AUTOSAR XML (schema 00047)
package /Svc_StbM/ClientServerInterfaces
  12 x client server interface:
    GlobalTime_Master_CertTime: is-service=true
      6 x operation, all with possible-error=[GlobalTime_Master_CertTime/E_NOT_OK, GlobalTime_Master_CertTime/E_OK]:
        GetMasterConfig
          arg masterConfig: type=StbM_MasterConfigType, direction=OUT
        SetGlobalTime
          arg timeStamp: type=StbM_TimeStampType, direction=IN
          arg userData: type=StbM_UserDataType, direction=IN
        SetRateCorrection
          arg rateDeviation: type=StbM_RateDeviationType, direction=IN
        SetUserData
          arg userData: type=StbM_UserDataType, direction=IN
        TriggerTimeTransmission
        UpdateGlobalTime
          arg timeStamp: type=StbM_TimeStampType, direction=IN
          arg userData: type=StbM_UserDataType, direction=IN
      error E_NOT_OK: error-code=1
      error E_OK: error-code=0
    GlobalTime_Master_Offset0: is-service=true
      7 x operation, all with possible-error=[GlobalTime_Master_Offset0/E_NOT_OK, GlobalTime_Master_Offset0/E_OK]:
        GetMasterConfig
          arg masterConfig: type=StbM_MasterConfigType, direction=OUT
        SetGlobalTime
          arg timeStamp: type=StbM_TimeStampType, direction=IN
          arg userData: type=StbM_UserDataType, direction=IN
        SetOffset
          arg timeStamp: type=StbM_TimeStampType, direction=IN
          arg userData: type=StbM_UserDataType, direction=IN
        SetRateCorrection
          arg rateDeviation: type=StbM_RateDeviationType, direction=IN
        SetUserData
          arg userData: type=StbM_UserDataType, direction=IN
        TriggerTimeTransmission
        UpdateGlobalTime
          arg timeStamp: type=StbM_TimeStampType, direction=IN
          arg userData: type=StbM_UserDataType, direction=IN
      error E_NOT_OK: error-code=1
      error E_OK: error-code=0
    GlobalTime_Master_Provider0: is-service=true
      6 x operation, all with possible-error=[GlobalTime_Master_Provider0/E_NOT_OK, GlobalTime_Master_Provider0/E_OK]:
        GetMasterConfig
          arg masterConfig: type=StbM_MasterConfigType, direction=OUT
        SetGlobalTime
          arg timeStamp: type=StbM_TimeStampType, direction=IN
          arg userData: type=StbM_UserDataType, direction=IN
        SetRateCorrection
          arg rateDeviation: type=StbM_RateDeviationType, direction=IN
        SetUserData
          arg userData: type=StbM_UserDataType, direction=IN
        TriggerTimeTransmission
        UpdateGlobalTime
          arg timeStamp: type=StbM_TimeStampType, direction=IN
          arg userData: type=StbM_UserDataType, direction=IN
      error E_NOT_OK: error-code=1
      error E_OK: error-code=0
    GlobalTime_Master_Provider1: is-service=true
      6 x operation, all with possible-error=[GlobalTime_Master_Provider1/E_NOT_OK, GlobalTime_Master_Provider1/E_OK]:
        GetMasterConfig
          arg masterConfig: type=StbM_MasterConfigType, direction=OUT
        SetGlobalTime
          arg timeStamp: type=StbM_TimeStampType, direction=IN
          arg userData: type=StbM_UserDataType, direction=IN
        SetRateCorrection
          arg rateDeviation: type=StbM_RateDeviationType, direction=IN
        SetUserData
          arg userData: type=StbM_UserDataType, direction=IN
        TriggerTimeTransmission
        UpdateGlobalTime
          arg timeStamp: type=StbM_TimeStampType, direction=IN
          arg userData: type=StbM_UserDataType, direction=IN
      error E_NOT_OK: error-code=1
      error E_OK: error-code=0
    GlobalTime_Slave_CertTime: is-service=true
      5 x operation, all with possible-error=[GlobalTime_Slave_CertTime/E_NOT_OK, GlobalTime_Slave_CertTime/E_OK]:
        GetCurrentTime
          arg timeStamp: type=StbM_TimeStampType, direction=OUT
          arg userData: type=StbM_UserDataType, direction=OUT
        GetCurrentTimeExtended
          arg timeStamp: type=StbM_TimeStampExtendedType, direction=OUT
          arg userData: type=StbM_UserDataType, direction=OUT
        GetRateDeviation
          arg rateDeviation: type=StbM_RateDeviationType, direction=OUT
        GetTimeBaseStatus
          arg syncTimeBaseStatus: type=StbM_TimeBaseStatusType, direction=OUT
          arg offsetTimeBaseStatus: type=StbM_TimeBaseStatusType, direction=OUT
        GetTimeLeap
          arg timeJump: type=StbM_TimeDiffType, direction=OUT
      error E_NOT_OK: error-code=1
      error E_OK: error-code=0
    GlobalTime_Slave_Client0: is-service=true
      6 x operation, all with possible-error=[GlobalTime_Slave_Client0/E_NOT_OK, GlobalTime_Slave_Client0/E_OK]:
        GetCurrentTime
          arg timeStamp: type=StbM_TimeStampType, direction=OUT
          arg userData: type=StbM_UserDataType, direction=OUT
        GetCurrentTimeExtended
          arg timeStamp: type=StbM_TimeStampExtendedType, direction=OUT
          arg userData: type=StbM_UserDataType, direction=OUT
        GetRateDeviation
          arg rateDeviation: type=StbM_RateDeviationType, direction=OUT
        GetSyncTimeRecordHead
          arg syncRecordTableHead: type=StbM_SyncRecordTableHeadType, direction=OUT
        GetTimeBaseStatus
          arg syncTimeBaseStatus: type=StbM_TimeBaseStatusType, direction=OUT
          arg offsetTimeBaseStatus: type=StbM_TimeBaseStatusType, direction=OUT
        GetTimeLeap
          arg timeJump: type=StbM_TimeDiffType, direction=OUT
      error E_NOT_OK: error-code=1
      error E_OK: error-code=0
    GlobalTime_Slave_Offset0: is-service=true
      5 x operation, all with possible-error=[GlobalTime_Slave_Offset0/E_NOT_OK, GlobalTime_Slave_Offset0/E_OK]:
        GetCurrentTime
          arg timeStamp: type=StbM_TimeStampType, direction=OUT
          arg userData: type=StbM_UserDataType, direction=OUT
        GetCurrentTimeExtended
          arg timeStamp: type=StbM_TimeStampExtendedType, direction=OUT
          arg userData: type=StbM_UserDataType, direction=OUT
        GetRateDeviation
          arg rateDeviation: type=StbM_RateDeviationType, direction=OUT
        GetTimeBaseStatus
          arg syncTimeBaseStatus: type=StbM_TimeBaseStatusType, direction=OUT
          arg offsetTimeBaseStatus: type=StbM_TimeBaseStatusType, direction=OUT
        GetTimeLeap
          arg timeJump: type=StbM_TimeDiffType, direction=OUT
      error E_NOT_OK: error-code=1
      error E_OK: error-code=0
    GlobalTime_Slave_Provider0: is-service=true
      5 x operation, all with possible-error=[GlobalTime_Slave_Provider0/E_NOT_OK, GlobalTime_Slave_Provider0/E_OK]:
        GetCurrentTime
          arg timeStamp: type=StbM_TimeStampType, direction=OUT
          arg userData: type=StbM_UserDataType, direction=OUT
        GetCurrentTimeExtended
          arg timeStamp: type=StbM_TimeStampExtendedType, direction=OUT
          arg userData: type=StbM_UserDataType, direction=OUT
        GetRateDeviation
          arg rateDeviation: type=StbM_RateDeviationType, direction=OUT
        GetTimeBaseStatus
          arg syncTimeBaseStatus: type=StbM_TimeBaseStatusType, direction=OUT
          arg offsetTimeBaseStatus: type=StbM_TimeBaseStatusType, direction=OUT
        GetTimeLeap
          arg timeJump: type=StbM_TimeDiffType, direction=OUT
      error E_NOT_OK: error-code=1
      error E_OK: error-code=0
    GlobalTime_Slave_Provider1: is-service=true
      5 x operation, all with possible-error=[GlobalTime_Slave_Provider1/E_NOT_OK, GlobalTime_Slave_Provider1/E_OK]:
        GetCurrentTime
          arg timeStamp: type=StbM_TimeStampType, direction=OUT
          arg userData: type=StbM_UserDataType, direction=OUT
        GetCurrentTimeExtended
          arg timeStamp: type=StbM_TimeStampExtendedType, direction=OUT
          arg userData: type=StbM_UserDataType, direction=OUT
        GetRateDeviation
          arg rateDeviation: type=StbM_RateDeviationType, direction=OUT
        GetTimeBaseStatus
          arg syncTimeBaseStatus: type=StbM_TimeBaseStatusType, direction=OUT
          arg offsetTimeBaseStatus: type=StbM_TimeBaseStatusType, direction=OUT
        GetTimeLeap
          arg timeJump: type=StbM_TimeDiffType, direction=OUT
      error E_NOT_OK: error-code=1
      error E_OK: error-code=0
    MeasurementNotification_Client0
      operation SetSyncTimeRecordTable: possible-error=[MeasurementNotification_Client0/E_NOT_OK, MeasurementNotification_Client0/E_OK]
        arg syncRecordTableBlock: type=StbM_SyncRecordTableBlockType, direction=IN
      error E_NOT_OK: error-code=1
      error E_OK: error-code=0
    StartTimer: is-service=true
      operation StartTimer: possible-error=[StartTimer/E_NOT_OK, StartTimer/E_OK]
        arg expireTime: type=StbM_TimeStampType, direction=IN
      error E_NOT_OK: error-code=1
      error E_OK: error-code=0
    TimeNotification: is-service=true
      operation NotifyTime: possible-error=[TimeNotification/E_NOT_OK, TimeNotification/E_OK]
        arg deviationTime: type=StbM_TimeDiffType, direction=IN
      error E_NOT_OK: error-code=1
      error E_OK: error-code=0
package /Svc_StbM/ImplementationDataTypes
  14 x impl type:
    StbM_CustomerIdType: category=VALUE, base-type=uint16, is-struct-with-optional-element=false
    StbM_MasterConfigType: category=VALUE, base-type=uint8, is-struct-with-optional-element=false
    StbM_OffsetRecordTableBlockType: category=STRUCTURE, is-struct-with-optional-element=true
      element GlbSeconds: category=VALUE, base-type=uint32
      element GlbNanoSeconds: category=VALUE, base-type=uint32
      element TimeBaseStatus: category=VALUE, base-type=uint8
    StbM_OffsetRecordTableHeadType: category=STRUCTURE, is-struct-with-optional-element=true
      element OffsetTimeDomain: category=VALUE, base-type=uint8
    StbM_RateDeviationType: category=VALUE, base-type=sint16, is-struct-with-optional-element=false
    StbM_SyncRecordTableBlockType: category=STRUCTURE, is-struct-with-optional-element=true
      8 x element, all with category=VALUE:
        GlbSeconds: base-type=uint32
        GlbNanoSeconds: base-type=uint32
        TimeBaseStatus: base-type=uint8
        VirtualLocalTimeLow: base-type=uint32
        RateDeviation: base-type=sint16
        LocSeconds: base-type=uint32
        LocNanoSeconds: base-type=uint32
        PathDelay: base-type=uint32
    StbM_SyncRecordTableHeadType: category=STRUCTURE, is-struct-with-optional-element=true
      element SynchronizedTimeDomain: category=VALUE, base-type=uint8
      element HWfrequency: category=VALUE, base-type=uint32
      element HWprescaler: category=VALUE, base-type=uint32
    StbM_SynchronizedTimeBaseType: category=VALUE, base-type=uint16, is-struct-with-optional-element=false
    StbM_TimeBaseNotificationType: category=VALUE, base-type=uint32, is-struct-with-optional-element=false
    StbM_TimeBaseStatusType: category=VALUE, base-type=uint8, is-struct-with-optional-element=false
    StbM_TimeDiffType: category=VALUE, base-type=sint32, is-struct-with-optional-element=false
    StbM_TimeStampExtendedType: category=STRUCTURE, is-struct-with-optional-element=true
      element timeBaseStatus: category=VALUE, base-type=uint8
      element nanoseconds: category=VALUE, base-type=uint32
      element seconds: category=VALUE, base-type=uint64
    StbM_TimeStampType: category=STRUCTURE, is-struct-with-optional-element=true
      4 x element, all with category=VALUE:
        timeBaseStatus: base-type=uint8
        nanoseconds: base-type=uint32
        seconds: base-type=uint32
        secondsHi: base-type=uint16
    StbM_UserDataType: category=STRUCTURE, is-struct-with-optional-element=true
      4 x element, all with category=VALUE:
        userDataLength: base-type=uint16
        userByte{0..2}: base-type=uint8
package /Svc_StbM/SenderReceiverInterfaces
  sender receiver interface StatusNotification
    data eventNotification: type=StbM_TimeBaseNotificationType, init-value=0
package /Svc_StbM/SwComponentTypes
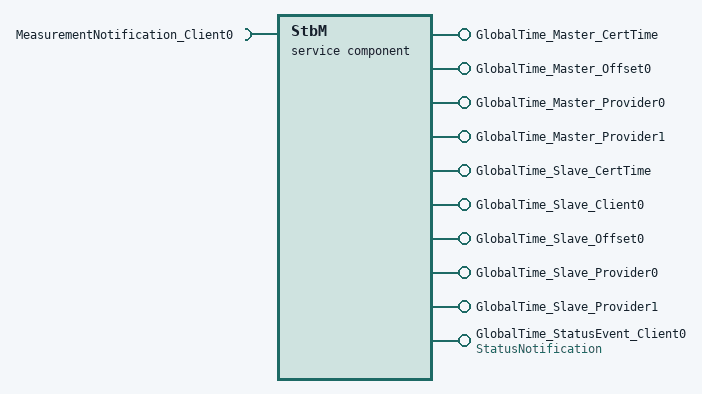
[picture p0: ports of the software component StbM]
  service sw component type StbM
    10 x provide port:
      GlobalTime_Master_CertTime: provided-interface=GlobalTime_Master_CertTime
        provided-com-specs:
          operation=GlobalTime_Master_CertTime/GetMasterConfig, queue-length=1
          operation=GlobalTime_Master_CertTime/SetGlobalTime, queue-length=1
          operation=GlobalTime_Master_CertTime/SetRateCorrection, queue-length=1
          operation=GlobalTime_Master_CertTime/SetUserData, queue-length=1
          operation=GlobalTime_Master_CertTime/TriggerTimeTransmission, queue-length=1
          operation=GlobalTime_Master_CertTime/UpdateGlobalTime, queue-length=1
      GlobalTime_Master_Offset0: provided-interface=GlobalTime_Master_Offset0
        provided-com-specs:
          operation=GlobalTime_Master_Offset0/GetMasterConfig, queue-length=1
          operation=GlobalTime_Master_Offset0/SetGlobalTime, queue-length=1
          operation=SetOffset, queue-length=1
          operation=GlobalTime_Master_Offset0/SetRateCorrection, queue-length=1
          operation=GlobalTime_Master_Offset0/SetUserData, queue-length=1
          operation=GlobalTime_Master_Offset0/TriggerTimeTransmission, queue-length=1
          operation=GlobalTime_Master_Offset0/UpdateGlobalTime, queue-length=1
      GlobalTime_Master_Provider0: provided-interface=GlobalTime_Master_Provider0
        provided-com-specs:
          operation=GlobalTime_Master_Provider0/GetMasterConfig, queue-length=1
          operation=GlobalTime_Master_Provider0/SetGlobalTime, queue-length=1
          operation=GlobalTime_Master_Provider0/SetRateCorrection, queue-length=1
          operation=GlobalTime_Master_Provider0/SetUserData, queue-length=1
          operation=GlobalTime_Master_Provider0/TriggerTimeTransmission, queue-length=1
          operation=GlobalTime_Master_Provider0/UpdateGlobalTime, queue-length=1
      GlobalTime_Master_Provider1: provided-interface=GlobalTime_Master_Provider1
        provided-com-specs:
          operation=GlobalTime_Master_Provider1/GetMasterConfig, queue-length=1
          operation=GlobalTime_Master_Provider1/SetGlobalTime, queue-length=1
          operation=GlobalTime_Master_Provider1/SetRateCorrection, queue-length=1
          operation=GlobalTime_Master_Provider1/SetUserData, queue-length=1
          operation=GlobalTime_Master_Provider1/TriggerTimeTransmission, queue-length=1
          operation=GlobalTime_Master_Provider1/UpdateGlobalTime, queue-length=1
      GlobalTime_Slave_CertTime: provided-interface=GlobalTime_Slave_CertTime
        provided-com-specs:
          operation=GlobalTime_Slave_CertTime/GetCurrentTime, queue-length=1
          operation=GlobalTime_Slave_CertTime/GetCurrentTimeExtended, queue-length=1
          operation=GlobalTime_Slave_CertTime/GetRateDeviation, queue-length=1
          operation=GlobalTime_Slave_CertTime/GetTimeBaseStatus, queue-length=1
          operation=GlobalTime_Slave_CertTime/GetTimeLeap, queue-length=1
      GlobalTime_Slave_Client0: provided-interface=GlobalTime_Slave_Client0
        provided-com-specs:
          operation=GlobalTime_Slave_Client0/GetCurrentTime, queue-length=1
          operation=GlobalTime_Slave_Client0/GetCurrentTimeExtended, queue-length=1
          operation=GetSyncTimeRecordHead, queue-length=1
          operation=GlobalTime_Slave_Client0/GetRateDeviation, queue-length=1
          operation=GlobalTime_Slave_Client0/GetTimeBaseStatus, queue-length=1
          operation=GlobalTime_Slave_Client0/GetTimeLeap, queue-length=1
      GlobalTime_Slave_Offset0: provided-interface=GlobalTime_Slave_Offset0
        provided-com-specs:
          operation=GlobalTime_Slave_Offset0/GetCurrentTime, queue-length=1
          operation=GlobalTime_Slave_Offset0/GetCurrentTimeExtended, queue-length=1
          operation=GlobalTime_Slave_Offset0/GetRateDeviation, queue-length=1
          operation=GlobalTime_Slave_Offset0/GetTimeBaseStatus, queue-length=1
          operation=GlobalTime_Slave_Offset0/GetTimeLeap, queue-length=1
      GlobalTime_Slave_Provider0: provided-interface=GlobalTime_Slave_Provider0
        provided-com-specs:
          operation=GlobalTime_Slave_Provider0/GetCurrentTime, queue-length=1
          operation=GlobalTime_Slave_Provider0/GetCurrentTimeExtended, queue-length=1
          operation=GlobalTime_Slave_Provider0/GetRateDeviation, queue-length=1
          operation=GlobalTime_Slave_Provider0/GetTimeBaseStatus, queue-length=1
          operation=GlobalTime_Slave_Provider0/GetTimeLeap, queue-length=1
      GlobalTime_Slave_Provider1: provided-interface=GlobalTime_Slave_Provider1
        provided-com-specs:
          operation=GlobalTime_Slave_Provider1/GetCurrentTime, queue-length=1
          operation=GlobalTime_Slave_Provider1/GetCurrentTimeExtended, queue-length=1
          operation=GlobalTime_Slave_Provider1/GetRateDeviation, queue-length=1
          operation=GlobalTime_Slave_Provider1/GetTimeBaseStatus, queue-length=1
          operation=GlobalTime_Slave_Provider1/GetTimeLeap, queue-length=1
      GlobalTime_StatusEvent_Client0: nonqueued-sender-com-spec=data-element=eventNotification, provided-interface=StatusNotification
    require port MeasurementNotification_Client0: client-com-spec=SetSyncTimeRecordTable, required-interface=MeasurementNotification_Client0
    behavior StbMInternalBehavior: handle-termination-and-restart=NO-SUPPORT, included-data-type-set
      51 x operation invoked event:
        OIE_GlobalTime_Master_CertTime_GetMasterConfig: start-on-event=GetMasterConfig, operation=GlobalTime_Master_CertTime.GetMasterConfig
        OIE_GlobalTime_Master_CertTime_SetGlobalTime: start-on-event=SetGlobalTime, operation=GlobalTime_Master_CertTime.SetGlobalTime
        OIE_GlobalTime_Master_CertTime_SetRateCorrection: start-on-event=SetRateCorrection, operation=GlobalTime_Master_CertTime.SetRateCorrection
        OIE_GlobalTime_Master_CertTime_SetUserData: start-on-event=SetUserData, operation=GlobalTime_Master_CertTime.SetUserData
        OIE_GlobalTime_Master_CertTime_TriggerTimeTransmission: start-on-event=TriggerTimeTransmission, operation=GlobalTime_Master_CertTime.TriggerTimeTransmission
        OIE_GlobalTime_Master_CertTime_UpdateGlobalTime: start-on-event=UpdateGlobalTime, operation=GlobalTime_Master_CertTime.UpdateGlobalTime
        OIE_GlobalTime_Master_Offset0_GetMasterConfig: start-on-event=GetMasterConfig, operation=GlobalTime_Master_Offset0.GetMasterConfig
        OIE_GlobalTime_Master_Offset0_SetGlobalTime: start-on-event=SetGlobalTime, operation=GlobalTime_Master_Offset0.SetGlobalTime
        OIE_GlobalTime_Master_Offset0_SetOffset: start-on-event=SetOffset, operation=GlobalTime_Master_Offset0.SetOffset
        OIE_GlobalTime_Master_Offset0_SetRateCorrection: start-on-event=SetRateCorrection, operation=GlobalTime_Master_Offset0.SetRateCorrection
        OIE_GlobalTime_Master_Offset0_SetUserData: start-on-event=SetUserData, operation=GlobalTime_Master_Offset0.SetUserData
        OIE_GlobalTime_Master_Offset0_TriggerTimeTransmission: start-on-event=TriggerTimeTransmission, operation=GlobalTime_Master_Offset0.TriggerTimeTransmission
        OIE_GlobalTime_Master_Offset0_UpdateGlobalTime: start-on-event=UpdateGlobalTime, operation=GlobalTime_Master_Offset0.UpdateGlobalTime
        OIE_GlobalTime_Master_Provider0_GetMasterConfig: start-on-event=GetMasterConfig, operation=GlobalTime_Master_Provider0.GetMasterConfig
        OIE_GlobalTime_Master_Provider0_SetGlobalTime: start-on-event=SetGlobalTime, operation=GlobalTime_Master_Provider0.SetGlobalTime
        OIE_GlobalTime_Master_Provider0_SetRateCorrection: start-on-event=SetRateCorrection, operation=GlobalTime_Master_Provider0.SetRateCorrection
        OIE_GlobalTime_Master_Provider0_SetUserData: start-on-event=SetUserData, operation=GlobalTime_Master_Provider0.SetUserData
        OIE_GlobalTime_Master_Provider0_TriggerTimeTransmission: start-on-event=TriggerTimeTransmission, operation=GlobalTime_Master_Provider0.TriggerTimeTransmission
        OIE_GlobalTime_Master_Provider0_UpdateGlobalTime: start-on-event=UpdateGlobalTime, operation=GlobalTime_Master_Provider0.UpdateGlobalTime
        OIE_GlobalTime_Master_Provider1_GetMasterConfig: start-on-event=GetMasterConfig, operation=GlobalTime_Master_Provider1.GetMasterConfig
        OIE_GlobalTime_Master_Provider1_SetGlobalTime: start-on-event=SetGlobalTime, operation=GlobalTime_Master_Provider1.SetGlobalTime
        OIE_GlobalTime_Master_Provider1_SetRateCorrection: start-on-event=SetRateCorrection, operation=GlobalTime_Master_Provider1.SetRateCorrection
        OIE_GlobalTime_Master_Provider1_SetUserData: start-on-event=SetUserData, operation=GlobalTime_Master_Provider1.SetUserData
        OIE_GlobalTime_Master_Provider1_TriggerTimeTransmission: start-on-event=TriggerTimeTransmission, operation=GlobalTime_Master_Provider1.TriggerTimeTransmission
        OIE_GlobalTime_Master_Provider1_UpdateGlobalTime: start-on-event=UpdateGlobalTime, operation=GlobalTime_Master_Provider1.UpdateGlobalTime
        OIE_GlobalTime_Slave_CertTime_GetCurrentTime: start-on-event=GetCurrentTime, operation=GlobalTime_Slave_CertTime.GetCurrentTime
        OIE_GlobalTime_Slave_CertTime_GetCurrentTimeExtended: start-on-event=GetCurrentTimeExtended, operation=GlobalTime_Slave_CertTime.GetCurrentTimeExtended
        OIE_GlobalTime_Slave_CertTime_GetRateDeviation: start-on-event=GetRateDeviation, operation=GlobalTime_Slave_CertTime.GetRateDeviation
        OIE_GlobalTime_Slave_CertTime_GetTimeBaseStatus: start-on-event=GetTimeBaseStatus, operation=GlobalTime_Slave_CertTime.GetTimeBaseStatus
        OIE_GlobalTime_Slave_CertTime_GetTimeLeap: start-on-event=GetTimeLeap, operation=GlobalTime_Slave_CertTime.GetTimeLeap
        OIE_GlobalTime_Slave_Client0_GetCurrentTime: start-on-event=GetCurrentTime, operation=GlobalTime_Slave_Client0.GetCurrentTime
        OIE_GlobalTime_Slave_Client0_GetCurrentTimeExtended: start-on-event=GetCurrentTimeExtended, operation=GlobalTime_Slave_Client0.GetCurrentTimeExtended
        OIE_GlobalTime_Slave_Client0_GetRateDeviation: start-on-event=GetRateDeviation, operation=GlobalTime_Slave_Client0.GetRateDeviation
        OIE_GlobalTime_Slave_Client0_GetSyncTimeRecordHead: start-on-event=GetSyncTimeRecordHead, operation=GlobalTime_Slave_Client0.GetSyncTimeRecordHead
        OIE_GlobalTime_Slave_Client0_GetTimeBaseStatus: start-on-event=GetTimeBaseStatus, operation=GlobalTime_Slave_Client0.GetTimeBaseStatus
        OIE_GlobalTime_Slave_Client0_GetTimeLeap: start-on-event=GetTimeLeap, operation=GlobalTime_Slave_Client0.GetTimeLeap
        OIE_GlobalTime_Slave_Offset0_GetCurrentTime: start-on-event=GetCurrentTime, operation=GlobalTime_Slave_Offset0.GetCurrentTime
        OIE_GlobalTime_Slave_Offset0_GetCurrentTimeExtended: start-on-event=GetCurrentTimeExtended, operation=GlobalTime_Slave_Offset0.GetCurrentTimeExtended
        OIE_GlobalTime_Slave_Offset0_GetRateDeviation: start-on-event=GetRateDeviation, operation=GlobalTime_Slave_Offset0.GetRateDeviation
        OIE_GlobalTime_Slave_Offset0_GetTimeBaseStatus: start-on-event=GetTimeBaseStatus, operation=GlobalTime_Slave_Offset0.GetTimeBaseStatus
        OIE_GlobalTime_Slave_Offset0_GetTimeLeap: start-on-event=GetTimeLeap, operation=GlobalTime_Slave_Offset0.GetTimeLeap
        OIE_GlobalTime_Slave_Provider0_GetCurrentTime: start-on-event=GetCurrentTime, operation=GlobalTime_Slave_Provider0.GetCurrentTime
        OIE_GlobalTime_Slave_Provider0_GetCurrentTimeExtended: start-on-event=GetCurrentTimeExtended, operation=GlobalTime_Slave_Provider0.GetCurrentTimeExtended
        OIE_GlobalTime_Slave_Provider0_GetRateDeviation: start-on-event=GetRateDeviation, operation=GlobalTime_Slave_Provider0.GetRateDeviation
        OIE_GlobalTime_Slave_Provider0_GetTimeBaseStatus: start-on-event=GetTimeBaseStatus, operation=GlobalTime_Slave_Provider0.GetTimeBaseStatus
        OIE_GlobalTime_Slave_Provider0_GetTimeLeap: start-on-event=GetTimeLeap, operation=GlobalTime_Slave_Provider0.GetTimeLeap
        OIE_GlobalTime_Slave_Provider1_GetCurrentTime: start-on-event=GetCurrentTime, operation=GlobalTime_Slave_Provider1.GetCurrentTime
        OIE_GlobalTime_Slave_Provider1_GetCurrentTimeExtended: start-on-event=GetCurrentTimeExtended, operation=GlobalTime_Slave_Provider1.GetCurrentTimeExtended
        OIE_GlobalTime_Slave_Provider1_GetRateDeviation: start-on-event=GetRateDeviation, operation=GlobalTime_Slave_Provider1.GetRateDeviation
        OIE_GlobalTime_Slave_Provider1_GetTimeBaseStatus: start-on-event=GetTimeBaseStatus, operation=GlobalTime_Slave_Provider1.GetTimeBaseStatus
        OIE_GlobalTime_Slave_Provider1_GetTimeLeap: start-on-event=GetTimeLeap, operation=GlobalTime_Slave_Provider1.GetTimeLeap
      port-api-options:
        {indirect-api=false, port-defined-argument-value{value=1, value-type=StbM_SynchronizedTimeBaseType}, port=GlobalTime_Master_Provider0}
        {indirect-api=false, port-defined-argument-value{value=16, value-type=StbM_SynchronizedTimeBaseType}, port=GlobalTime_Master_Offset0}
        {indirect-api=false, port-defined-argument-value{value=2, value-type=StbM_SynchronizedTimeBaseType}, port=GlobalTime_Master_Provider1}
        {indirect-api=false, port-defined-argument-value{value=3, value-type=StbM_SynchronizedTimeBaseType}, port=GlobalTime_Master_CertTime}
        {indirect-api=false, port-defined-argument-value{value=0, value-type=StbM_SynchronizedTimeBaseType}, port=GlobalTime_Slave_Client0}
        {indirect-api=false, port-defined-argument-value{value=1, value-type=StbM_SynchronizedTimeBaseType}, port=GlobalTime_Slave_Provider0}
        {indirect-api=false, port-defined-argument-value{value=16, value-type=StbM_SynchronizedTimeBaseType}, port=GlobalTime_Slave_Offset0}
        {indirect-api=false, port-defined-argument-value{value=2, value-type=StbM_SynchronizedTimeBaseType}, port=GlobalTime_Slave_Provider1}
        {indirect-api=false, port-defined-argument-value{value=3, value-type=StbM_SynchronizedTimeBaseType}, port=GlobalTime_Slave_CertTime}
      22 x runnable:
        BusGetCurrentTime: can-be-invoked-concurrently=true, symbol=StbM_BusGetCurrentTime
        BusSetGlobalTime: can-be-invoked-concurrently=true, symbol=StbM_BusSetGlobalTime
        GetCurrentTime: can-be-invoked-concurrently=true, symbol=StbM_GetCurrentTime
        GetCurrentTimeExtended: can-be-invoked-concurrently=true, symbol=StbM_GetCurrentTimeExtended
        GetCurrentVirtualLocalTime: can-be-invoked-concurrently=true, symbol=StbM_GetCurrentVirtualLocalTime
        GetMasterConfig: can-be-invoked-concurrently=true, symbol=StbM_GetMasterConfig
        GetOffset: can-be-invoked-concurrently=true, symbol=StbM_GetOffset
        GetOffsetTimeRecordHead: can-be-invoked-concurrently=true, symbol=StbM_GetOffsetTimeRecordHead
        GetRateDeviation: can-be-invoked-concurrently=true, symbol=StbM_GetRateDeviation
        GetSyncTimeRecordHead: can-be-invoked-concurrently=true, symbol=StbM_GetSyncTimeRecordHead
        GetTimeBaseStatus: can-be-invoked-concurrently=true, symbol=StbM_GetTimeBaseStatus
        GetTimeBaseUpdateCounter: can-be-invoked-concurrently=true, symbol=StbM_GetTimeBaseUpdateCounter
        GetTimeLeap: can-be-invoked-concurrently=true, symbol=StbM_GetTimeLeap
        MainFunction: minimum-start-interval=0.005, symbol=StbM_MainFunction
        SetGlobalTime: can-be-invoked-concurrently=true, symbol=StbM_SetGlobalTime
        SetOffset: can-be-invoked-concurrently=true, symbol=StbM_SetOffset
        SetRateCorrection: can-be-invoked-concurrently=true, symbol=StbM_SetRateCorrection
        SetUserData: can-be-invoked-concurrently=true, symbol=StbM_SetUserData
        StartTimer: can-be-invoked-concurrently=true, symbol=StbM_StartTimer
        StbM_Required_Port: can-be-invoked-concurrently=true, symbol=StbM_Required_Ports_Call
          data-send-points:
            access GlobalTime_StatusEvent_Client0: accessed-variable=GlobalTime_StatusEvent_Client0.eventNotification
          sync call MeasurementNotification_Client0: operation=MeasurementNotification_Client0.SetSyncTimeRecordTable
        TriggerTimeTransmission: can-be-invoked-concurrently=true, symbol=StbM_TriggerTimeTransmission
        UpdateGlobalTime: can-be-invoked-concurrently=true, symbol=StbM_UpdateGlobalTime
  swc implementation StbM_SwcImplementation: programming-language=C, sw-version=1.0.0, swc-bsw-mapping=SwcBswMapping_StbM, vendor-id=76, behavior=StbMInternalBehavior
    code-descriptors:
      code CodeDescriptor: artifact-descriptors=autosar-engineering-object={short-label=StbM_LibObjects, category=SWLIB, domain=AUTOSAR_STBM}
    resource consumption ResourceConsumption
  swc bsw mapping SwcBswMapping_StbM: bsw-behavior=BswInternalBehavior_StbM, swc-behavior=StbMInternalBehavior
    runnable-mappings:
      bsw-entity=BswCE_StbM_BusGetCurrentTime, swc-runnable=BusGetCurrentTime
      bsw-entity=BswCE_StbM_BusSetGlobalTime, swc-runnable=BusSetGlobalTime
      bsw-entity=BswCE_StbM_GetCurrentTime, swc-runnable=GetCurrentTime
      bsw-entity=BswCE_StbM_GetCurrentTimeExtended, swc-runnable=GetCurrentTimeExtended
      bsw-entity=BswCE_StbM_GetCurrentVirtualLocalTime, swc-runnable=GetCurrentVirtualLocalTime
      bsw-entity=BswCE_StbM_GetMasterConfig, swc-runnable=GetMasterConfig
      bsw-entity=BswCE_StbM_GetOffset, swc-runnable=GetOffset
      bsw-entity=BswCE_StbM_GetOffsetTimeRecordHead, swc-runnable=GetOffsetTimeRecordHead
      bsw-entity=BswCE_StbM_GetRateDeviation, swc-runnable=GetRateDeviation
      bsw-entity=BswCE_StbM_GetSyncTimeRecordHead, swc-runnable=GetSyncTimeRecordHead
      bsw-entity=BswCE_StbM_GetTimeBaseStatus, swc-runnable=GetTimeBaseStatus
      bsw-entity=BswCE_StbM_GetTimeBaseUpdateCounter, swc-runnable=GetTimeBaseUpdateCounter
      bsw-entity=BswCE_StbM_GetTimeLeap, swc-runnable=GetTimeLeap
      bsw-entity=BswSE_StbM_MainFunction, swc-runnable=MainFunction
      bsw-entity=BswCE_StbM_SetGlobalTime, swc-runnable=SetGlobalTime
      bsw-entity=BswCE_StbM_SetOffset, swc-runnable=SetOffset
      bsw-entity=BswCE_StbM_SetRateCorrection, swc-runnable=SetRateCorrection
      bsw-entity=BswCE_StbM_SetUserData, swc-runnable=SetUserData
      bsw-entity=BswCE_StbM_StartTimer, swc-runnable=StartTimer
      bsw-entity=BswCE_StbM_TriggerTimeTransmission, swc-runnable=TriggerTimeTransmission
      bsw-entity=BswCE_StbM_UpdateGlobalTime, swc-runnable=UpdateGlobalTime
